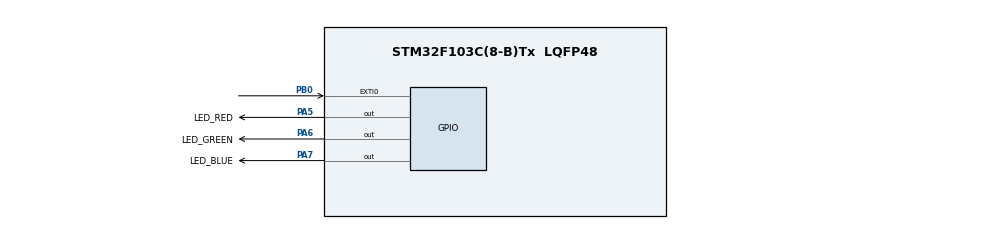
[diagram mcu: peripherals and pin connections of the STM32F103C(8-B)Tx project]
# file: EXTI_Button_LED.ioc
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Mcu.Family=STM32F1
Mcu.Name=STM32F103C(8-B)Tx
Mcu.Package=LQFP48
NVIC.EXTI0_IRQn=true\:0\:0\:false\:false\:true\:true\:true\:true
NVIC.PriorityGroup=NVIC_PRIORITYGROUP_4
PA5.GPIO_Label=LED_RED
PA5.Signal=GPIO_Output
PA6.GPIO_Label=LED_GREEN
PA6.Signal=GPIO_Output
PA7.GPIO_Label=LED_BLUE
PA7.Signal=GPIO_Output
PB0.GPIO_ModeDefaultEXTI=GPIO_MODE_IT_FALLING
PB0.GPIO_PuPd=GPIO_PULLUP
PB0.Signal=GPXTI0
ProjectManager.HeapSize=0x200
ProjectManager.StackSize=0x400
ProjectManager.TargetToolchain=STM32CubeIDE
RCC.APB1Freq_Value=8000000
RCC.APB2Freq_Value=8000000
board=custom

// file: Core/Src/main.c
/* USER CODE BEGIN Header */
/**
  ******************************************************************************
  * @file           : main.c
  * @brief          : Main program body
  ******************************************************************************
  * @attention
  *
  * Copyright (c) 2025 STMicroelectronics.
  * All rights reserved.
  *
  * This software is licensed under terms that can be found in the LICENSE file
  * in the root directory of this software component.
  * If no LICENSE file comes with this software, it is provided AS-IS.
  *
  ******************************************************************************
  */
/* USER CODE END Header */
#include "main.h"

void SystemClock_Config(void);
static void MX_GPIO_Init(void);

int main(void)
{
  /* MCU Configuration--------------------------------------------------------*/

  /* Reset of all peripherals, Initializes the Flash interface and the Systick. */
  HAL_Init();

  /* Configure the system clock */
  SystemClock_Config();

  /* Initialize all configured peripherals */
  MX_GPIO_Init();

  /* Infinite loop */
  while (1)
  {
    HAL_GPIO_TogglePin(GPIOA, LED_BLUE_Pin);
    HAL_Delay(1000);
  }
}

void SystemClock_Config(void)
{
  RCC_OscInitTypeDef RCC_OscInitStruct = {0};
  RCC_ClkInitTypeDef RCC_ClkInitStruct = {0};

  /** Initializes the RCC Oscillators according to the specified parameters
  * in the RCC_OscInitTypeDef structure.
  */
  RCC_OscInitStruct.OscillatorType = RCC_OSCILLATORTYPE_HSI;
  RCC_OscInitStruct.HSIState = RCC_HSI_ON;
  RCC_OscInitStruct.HSICalibrationValue = RCC_HSICALIBRATION_DEFAULT;
  RCC_OscInitStruct.PLL.PLLState = RCC_PLL_NONE;
  if (HAL_RCC_OscConfig(&RCC_OscInitStruct) != HAL_OK)
  {
    Error_Handler();
  }

  /** Initializes the CPU, AHB and APB buses clocks
  */
  RCC_ClkInitStruct.ClockType = RCC_CLOCKTYPE_HCLK|RCC_CLOCKTYPE_SYSCLK
                              |RCC_CLOCKTYPE_PCLK1|RCC_CLOCKTYPE_PCLK2;
  RCC_ClkInitStruct.SYSCLKSource = RCC_SYSCLKSOURCE_HSI;
  RCC_ClkInitStruct.AHBCLKDivider = RCC_SYSCLK_DIV1;
  RCC_ClkInitStruct.APB1CLKDivider = RCC_HCLK_DIV1;
  RCC_ClkInitStruct.APB2CLKDivider = RCC_HCLK_DIV1;

  if (HAL_RCC_ClockConfig(&RCC_ClkInitStruct, FLASH_LATENCY_0) != HAL_OK)
  {
    Error_Handler();
  }
}

static void MX_GPIO_Init(void)
{
  GPIO_InitTypeDef GPIO_InitStruct = {0};

  /* GPIO Ports Clock Enable */
  __HAL_RCC_GPIOA_CLK_ENABLE();
  __HAL_RCC_GPIOB_CLK_ENABLE();

  /*Configure GPIO pin Output Level */
  HAL_GPIO_WritePin(GPIOA, LED_RED_Pin|LED_GREEN_Pin|LED_BLUE_Pin, GPIO_PIN_RESET);

  /*Configure GPIO pins : LED_RED_Pin LED_GREEN_Pin LED_BLUE_Pin */
  GPIO_InitStruct.Pin = LED_RED_Pin|LED_GREEN_Pin|LED_BLUE_Pin;
  GPIO_InitStruct.Mode = GPIO_MODE_OUTPUT_PP;
  GPIO_InitStruct.Pull = GPIO_NOPULL;
  GPIO_InitStruct.Speed = GPIO_SPEED_FREQ_LOW;
  HAL_GPIO_Init(GPIOA, &GPIO_InitStruct);

  /*Configure GPIO pin : PB0 */
  GPIO_InitStruct.Pin = GPIO_PIN_0;
  GPIO_InitStruct.Mode = GPIO_MODE_IT_FALLING;
  GPIO_InitStruct.Pull = GPIO_PULLUP;
  HAL_GPIO_Init(GPIOB, &GPIO_InitStruct);

  /* EXTI interrupt init*/
  HAL_NVIC_SetPriority(EXTI0_IRQn, 0, 0);
  HAL_NVIC_EnableIRQ(EXTI0_IRQn);

}

/* USER CODE BEGIN 4 */
uint8_t State = 0; // 0: red, 1: green, 2: blue
void SetLED(uint8_t S)
{
  HAL_GPIO_WritePin(GPIOA, LED_RED_Pin, (S==0) ? GPIO_PIN_SET : GPIO_PIN_RESET);
  HAL_GPIO_WritePin(GPIOA, LED_GREEN_Pin, (S==1) ? GPIO_PIN_SET : GPIO_PIN_RESET);
  HAL_GPIO_WritePin(GPIOA, LED_BLUE_Pin, (S==2) ? GPIO_PIN_SET : GPIO_PIN_RESET);
}

void HAL_GPIO_EXTI_Callback(uint16_t GPIO_Pin)
{
  static uint32_t last_tick = 0;
  if (GPIO_Pin == GPIO_PIN_0) // button
  {
    if (HAL_GetTick() - last_tick > 200) // debounce
    {
      State = (State + 1) % 3;
      SetLED(State);
    }
    last_tick = HAL_GetTick();
  }
}
/* USER CODE END 4 */

void Error_Handler(void)
{
  __disable_irq();
  while (1)
  {
  }
}
